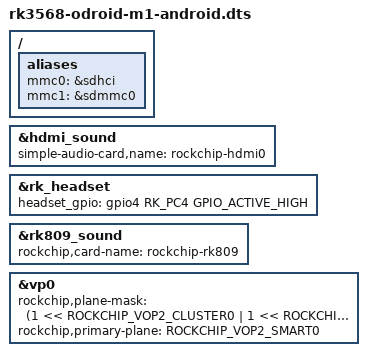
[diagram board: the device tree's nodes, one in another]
/*
 * Copyright (c) 2024 Hardkernel Co., Ltd.
 *
 */

#include "rk3568-odroid-m1.dtsi"
#include "rk3568-android.dtsi"
#include <dt-bindings/display/rockchip_vop.h>

/{
	aliases {
		mmc0 = &sdhci;
		mmc1 = &sdmmc0;
	};
};

&hdmi_sound {
	simple-audio-card,name = "rockchip-hdmi0";
};

&rk_headset {
	headset_gpio = <&gpio4 RK_PC4 GPIO_ACTIVE_HIGH>;
};

&rk809_sound {
	rockchip,card-name = "rockchip-rk809";
};

&vp0 {
	rockchip,plane-mask = <(1 << ROCKCHIP_VOP2_CLUSTER0
			| 1 << ROCKCHIP_VOP2_CLUSTER1
			| 1 << ROCKCHIP_VOP2_ESMART0
			| 1 << ROCKCHIP_VOP2_ESMART1
			| 1 << ROCKCHIP_VOP2_SMART0
			| 1 << ROCKCHIP_VOP2_SMART1)>;
	rockchip,primary-plane = <ROCKCHIP_VOP2_SMART0>;
};
